# G32R501 register map
Vendor: Geehy Semiconductor Co., Ltd.; Series: G32R5; File version: 1.0
CPU: CM55 r0p1, little endian, MPU, FPU, double-precision FPU, DSP, VTOR, 4 interrupt priority bits
Registers are 32-bit, read-write, reset 0x0 unless marked. A register's access mark holds for its fields unless they carry their own. Offsets are from the block's base; [hi:lo] are bit positions; {n}, {i} and the like mark numbered series.

## QSPI
Base 0x50026000
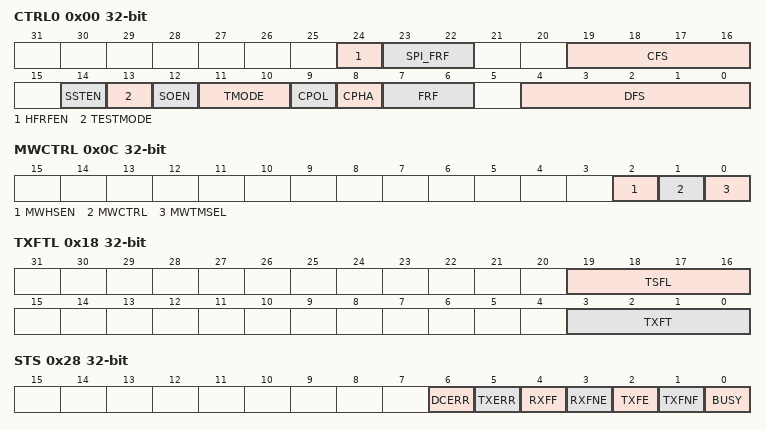
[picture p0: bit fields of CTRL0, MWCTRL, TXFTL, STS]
0x00 CTRL0 — Control Register 0
  [24] HFRFEN — Hyperbus Frame format Enable
  [23:22] SPI_FRF — Frame Format
  [19:16] CFS — Control Frame Size
  [14] SSTEN — Slave Select Toggle Enable
  [13] TESTMODE
  [12] SOEN — Slave Output Enable
  [11:10] TMODE — Transfer Mode
  [9] CPOL — Clock Polarity
  [8] CPHA — Clock Phase
  [7:6] FRF — Frame Format
  [4:0] DFS — Data Frame Size
0x04 CTRL1 — Control Register 1
  [15:0] NDF — Number of Data Frames
0x08 EN — SSI Enable Register
  [0] EN — QSPI Enable
0x0C MWCTRL — Microwire Control Register
  [2] MWHSEN — Microwire Handshaking Enable
  [1] MWCTRL — Microwire Control
  [0] MWTMSEL — Microwire Transfer Mode Select
0x10 SEN — Slave Enable Register
  [0] SEN — Slave Enable
0x14 BR — Baud Rate Select Register
  [15:0] CLKDIV — QSPI Clock Divider
0x18 TXFTL — Transmit FIFO Threshold Level Register
  [19:16] TSFL — Transfer Start FIFO Level
  [3:0] TXFT — Transmit FIFO Threshold
0x1C RXFTL — Receive FIFO Threshold Level Register
  [3:0] RXFT — Receive FIFO Threshold
0x20 TXFL ro — Transmit FIFO Level Register
  [4:0] TXFL — Transmit FIFO Level
0x24 RXFL ro — Receive FIFO Level Register
  [4:0] RXFL — Receive FIFO Level
0x28 STS ro — Status Register
  [6] DCERR — Data Collision Error
  [5] TXERR — Transmission Error
  [4] RXFF — Receive FIFO Full
  [3] RXFNE — Receive FIFO Not Empty
  [2] TXFE — Transmit FIFO Empty
  [1] TXFNF — Transmit FIFO Not Full
  [0] BUSY — QSPI Busy Flag
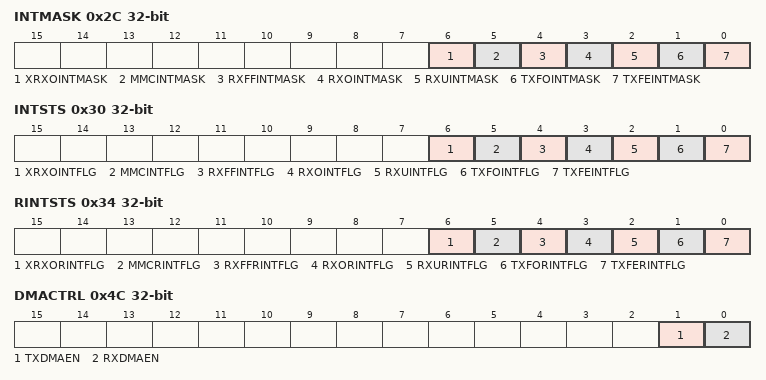
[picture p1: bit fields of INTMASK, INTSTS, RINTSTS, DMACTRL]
0x2C INTMASK — Interrupt Mask Register
  [6] XRXOINTMASK — XIP Receive FIFO Overflow Interrupt Mask
  [5] MMCINTMASK — Multi-Master Contention Interrupt Mask
  [4] RXFFINTMASK — Receive FIFO Full Interrupt Mask
  [3] RXOINTMASK — Receive FIFO Overflow Interrupt Mask
  [2] RXUINTMASK — Receive FIFO Underflow Interrupt Mask
  [1] TXFOINTMASK — Transmit FIFO Overflow Interrupt Mask
  [0] TXFEINTMASK — Transmit FIFO Empty Interrupt Mask
0x30 INTSTS ro — Interrupt Status Register
  [6] XRXOINTFLG — XIP Receive FIFO Overflow Interrupt Flag
  [5] MMCINTFLG — Multi-Master Contention Interrupt Flag
  [4] RXFFINTFLG — Receive FIFO Full Interrupt Flag
  [3] RXOINTFLG — Receive FIFO Overflow Interrupt Flag
  [2] RXUINTFLG — Receive FIFO Underflow Interrupt Flag
  [1] TXFOINTFLG — Transmit FIFO Overflow Interrupt Flag
  [0] TXFEINTFLG — Transmit FIFO Empty Interrupt Flag
0x34 RINTSTS ro — Raw Interrupt Status Register
  [6] XRXORINTFLG — XIP Receive FIFO Overflow Raw Interrupt Flag
  [5] MMCRINTFLG — Multi-Master Contention Raw Interrupt Flag
  [4] RXFFRINTFLG — Receive FIFO Full Raw Interrupt Mask
  [3] RXORINTFLG — Receive FIFO Overflow Interrupt Flag
  [2] RXURINTFLG — Receive FIFO Underflow Raw Interrupt Flag
  [1] TXFORINTFLG — Transmit FIFO Overflow Raw Interrupt Flag
  [0] TXFERINTFLG — Transmit FIFO Empty Raw Interrupt Flag
0x38 TXFOINTCLR ro — Transmit FIFO Overflow Interrupt Clear Register
  [0] TXFOINTCLR — Transmit FIFO Overflow Interrupt Clear
0x3C RXFOINTCLR ro — Receive FIFO Overflow Interrupt Clear Register
  [0] RXFOINTCLR — Receive FIFO Overflow Interrupt Clear
0x40 RXFUINTCLR ro — Receive FIFO Underflow Interrupt Clear Register
  [0] RXFUINTCLR — Receive FIFO Underflow Interrupt Clear
0x44 MINTCLR ro — Multi-Master Interrupt Clear Register
  [0] MMCINTCLR — Multi-Master Contention Interrupt Clear
0x48 INTCLR ro — Interrupt Clear Register
  [0] INTCLR — Interrupts Clear
0x4C DMACTRL — DMA Control Register
  [1] TXDMAEN — Transmit DMA Enable
  [0] RXDMAEN — Receive DMA Enable
0x50 DMATXDL — DMA Transmit Data Level Register
  [3:0] DMATXDL — DMA Transmit Data Level
0x54 DMARXDL — DMA Receive Data Level Register
  [3:0] DMARXDL — DMA Receive Data Level
0x58 IDCODE ro reset 0xFFFFFFFF — Identification Code Register
  [31:0] IDCODE — Identification Code
0x5C CV ro reset 0x3130312A — Component Version Register
  [31:0] CV — Component Version
{0x60+4i} DATA{i} (i=0..35)
  [31:0] DATA{i} — Data
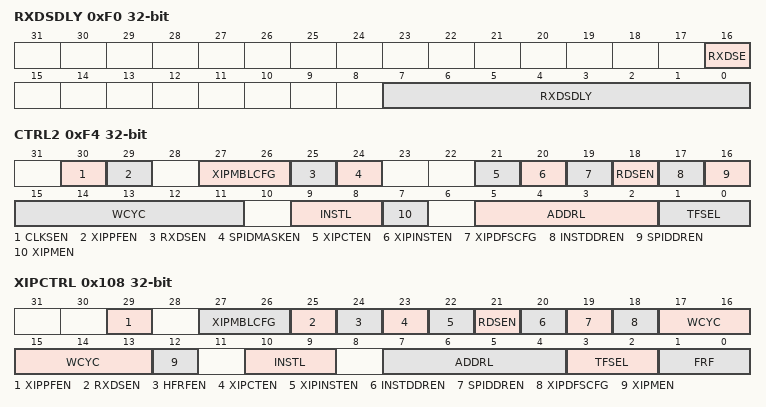
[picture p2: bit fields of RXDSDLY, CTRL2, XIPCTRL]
0xF0 RXDSDLY ro — RX Sample Delay Register
  [16] RXDSE — Receive Data Sampling Edge
  [7:0] RXDSDLY — Receive Data Sample Delay
0xF4 CTRL2 — Control Register 2
  [30] CLKSEN — Clock Stretch Enable
  [29] XIPPFEN — XIP Pre-fetch Enable
  [27:26] XIPMBLCFG — RXD Signal Enable
  [25] RXDSEN — RXD Signal Enable
  [24] SPIDMASKEN — SPI Data Mask Enable
  [21] XIPCTEN — XIP Instruction Enable
  [20] XIPINSTEN — XIP Instruction Enable
  [19] XIPDFSCFG — DFS for XIP Transfer Configure
  [18] RDSEN — Read Data Strobe Enable
  [17] INSTDDREN — Instruction Phase DDR Transfer Enable
  [16] SPIDDREN — SPI DDR Transfer Enable
  [15:11] WCYC — Wait Cycle
  [9:8] INSTL — Instruction Length
  [7] XIPMEN — Mode bits Enable in XIP mode
  [5:2] ADDRL — Address Length
  [1:0] TFSEL — Address/Instruction Transfer Format Select
0xF8 TXDE — Transmit Data Drive Edge Register
  [7:0] TXDDE — Transmit Data Drive Edge
0xFC XIPMS — XIP Mode bits Sent Register
  [15:0] XIPMS — XIP Mode bits to Be Sent
0x100 XIPINCRINST — XIP INCR Instruction Register
  [15:0] XIPINCRINST — XIP Mode bits to Be Sent
0x104 XIPWRAPINST — XIP WRAP Instruction Register
  [15:0] XIPWRAPINST — XIP Mode bits to Be Sent
0x108 XIPCTRL — XIP Control Register
  [29] XIPPFEN — XIP Pre-fetch Enable
  [27:26] XIPMBLCFG — XIP Mode bits Length Configure
  [25] RXDSEN — RXD Signal Enable
  [24] HFRFEN — Hyperbus Frame format Enable
  [23] XIPCTEN — Continuous Transfer in XIP Mode Enable
  [22] XIPINSTEN — XIP Instruction Enable
  [21] RDSEN — Read Data Strobe Enable
  [20] INSTDDREN — Instruction Phase DDR Transfer Enable
  [19] SPIDDREN — SPI DDR Transfer Enable
  [18] XIPDFSCFG — DFS for XIP Transfer Configure
  [17:13] WCYC — Wait Cycle
  [12] XIPMEN — Mode bits Enable in XIP mode
  [10:9] INSTL — Instruction Length
  [7:4] ADDRL — Address Length
  [3:2] TFSEL — Address/Instruction Transfer Format Select
  [1:0] FRF — Frame Format
0x10C XIPSEN — XIP Slave Enable Register
  [0] SEN — Slave Enable
0x110 XIPRXFOINTCLR — XIP Receive FIFO Overflow Interrupt Clear Register
  [0] XIPRXFOINTCLR — XIP Receive FIFO Overflow Interrupt Clear
0x114 XIPTOV — XIP Time Out Value Register
  [7:0] XIPTOV — XIP Time Out Valu
0x300 XIP_EN
  [0] XIPEN — XIP Mode Enable
0x340 SWITCH
  [0] little_endian
